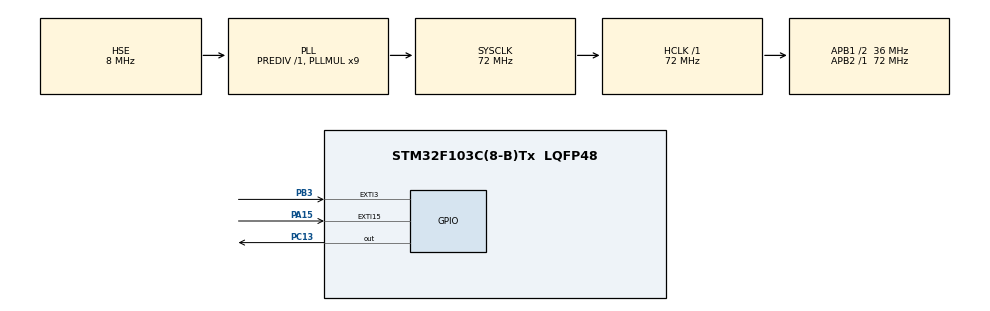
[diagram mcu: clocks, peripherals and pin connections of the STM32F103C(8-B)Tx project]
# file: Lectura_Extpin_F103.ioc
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Mcu.Family=STM32F1
Mcu.Name=STM32F103C(8-B)Tx
Mcu.Package=LQFP48
NVIC.EXTI15_10_IRQn=true\:0\:0\:false\:false\:true\:true\:true\:true
NVIC.EXTI3_IRQn=true\:0\:0\:false\:false\:true\:true\:true\:true
NVIC.PriorityGroup=NVIC_PRIORITYGROUP_4
PA13.Mode=Serial_Wire
PA13.Signal=SYS_JTMS-SWDIO
PA14.Mode=Serial_Wire
PA14.Signal=SYS_JTCK-SWCLK
PA15.Signal=GPXTI15
PB3.GPIO_ModeDefaultEXTI=GPIO_MODE_IT_FALLING
PB3.Signal=GPXTI3
PC13-TAMPER-RTC.Signal=GPIO_Output
PD0-OSC_IN.Mode=HSE-External-Oscillator
PD0-OSC_IN.Signal=RCC_OSC_IN
PD1-OSC_OUT.Mode=HSE-External-Oscillator
PD1-OSC_OUT.Signal=RCC_OSC_OUT
ProjectManager.HeapSize=0x200
ProjectManager.StackSize=0x400
ProjectManager.TargetToolchain=STM32CubeIDE
RCC.AHBFreq_Value=72000000
RCC.APB1CLKDivider=RCC_HCLK_DIV2
RCC.APB1Freq_Value=36000000
RCC.APB1TimFreq_Value=72000000
RCC.APB2Freq_Value=72000000
RCC.APB2TimFreq_Value=72000000
RCC.HCLKFreq_Value=72000000
RCC.PLLMUL=RCC_PLL_MUL9
RCC.PLLSourceVirtual=RCC_PLLSOURCE_HSE
RCC.SYSCLKFreq_VALUE=72000000
RCC.SYSCLKSource=RCC_SYSCLKSOURCE_PLLCLK
RCC.USBFreq_Value=72000000
TIM2.Period=720
TIM2.Prescaler=0
VP_TIM2_VS_ClockSourceINT.Mode=Internal
board=custom

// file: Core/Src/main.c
/* USER CODE BEGIN Header */
/**
  ******************************************************************************
  * @file           : main.c
  * @brief          : Main program body
  ******************************************************************************
  * @attention
  *
  * Copyright (c) 2023 STMicroelectronics.
  * All rights reserved.
  *
  * This software is licensed under terms that can be found in the LICENSE file
  * in the root directory of this software component.
  * If no LICENSE file comes with this software, it is provided AS-IS.
  *
  ******************************************************************************
  */
/* USER CODE END Header */
#include "main.h"

/* USER CODE BEGIN Includes */
#define TIMCLOCK   72000000
#define PRESCALAR  0
#define ARR 0x2D0
#define cant 150
/* USER CODE END Includes */

TIM_HandleTypeDef htim2;

/* USER CODE BEGIN PV */
uint32_t IC_Val1 = 0;
uint32_t IC_Val2 = 0;
uint32_t Difference = 0;
uint32_t usWidth[150];
float refClock=0;
float mFactor=0;
int cont=0;
int flag_pines=0;
int flag_menor=0;
uint32_t min=0;
int cant_min=0;
/* USER CODE END PV */

void SystemClock_Config(void);
static void MX_GPIO_Init(void);
static void MX_TIM2_Init(void);

/* USER CODE BEGIN 0 */
void HAL_GPIO_EXTI_Callback(uint16_t GPIO_Pin) //Interrupcion Externa del pin A1
{
	HAL_GPIO_WritePin(GPIOC, GPIO_PIN_13, GPIO_PIN_RESET);
    if(GPIO_Pin == GPIO_PIN_3) // Chequeo que sea el Pin B3 con bajo
    {
    	HAL_NVIC_DisableIRQ(EXTI3_IRQn); //desactiva las interrupciones externas
    	IC_Val1 =__HAL_TIM_GET_COUNTER(&htim2);

    }
    else if(GPIO_Pin == GPIO_PIN_15 && IC_Val1!=0) // Chequeo que sea el Pin A15 con alto
    {
    	IC_Val2 =__HAL_TIM_GET_COUNTER(&htim2);
    	HAL_NVIC_DisableIRQ(EXTI15_10_IRQn); //desactiva las interrupciones externas
    	flag_pines=1;//Activa la bendera para el calculo
    }
    HAL_GPIO_WritePin(GPIOC, GPIO_PIN_13, GPIO_PIN_SET);

}
/* USER CODE END 0 */

int main(void)
{

  /* MCU Configuration--------------------------------------------------------*/

  /* Reset of all peripherals, Initializes the Flash interface and the Systick. */
  HAL_Init();

  /* Configure the system clock */
  SystemClock_Config();

  /* Initialize all configured peripherals */
  MX_GPIO_Init();
  MX_TIM2_Init();
  /* USER CODE BEGIN 2 */
  HAL_TIM_Base_Start(&htim2);
  /* USER CODE END 2 */

  /* Infinite loop */
  /* USER CODE BEGIN WHILE */
  while (1)
  {
	  if (flag_pines==1)
	  {
		  if (IC_Val2 > IC_Val1)
		  {
			  Difference = IC_Val2-IC_Val1;
		  }
		  else if (IC_Val1 > IC_Val2)
		  {
			  Difference = (ARR - IC_Val1) + IC_Val2;
		  }
		  refClock = TIMCLOCK/(PRESCALAR+1);
		  //mFactor = 1000000/refClock;
		  if (cont<=cant)
		  {
			  usWidth[cont]= Difference;
			  IC_Val1=0;
			  IC_Val2=0;
			  cont++;
			  HAL_NVIC_EnableIRQ(EXTI3_IRQn);
			  HAL_NVIC_EnableIRQ(EXTI15_10_IRQn);
		  }
		  else
		  {
			  flag_menor=1;
		  }
		  flag_pines=0;
	  }
	  if (flag_menor==1)
	  {
		  min=usWidth[0];
		  for (int i=0;i<=149;i++)
		  {
			  if (usWidth[i]< min && usWidth[i]!=0)
			  {
				  min = usWidth[i];
			  }
		  }

		  for (int i=0;i<=149;i++)
		  {
			  if (usWidth[i]==min)
			  {
				  cant_min++;
			  }
		  }
		  flag_menor=0;
	  }
    /* USER CODE END WHILE */

  }
}

void SystemClock_Config(void)
{
  RCC_OscInitTypeDef RCC_OscInitStruct = {0};
  RCC_ClkInitTypeDef RCC_ClkInitStruct = {0};

  /** Initializes the RCC Oscillators according to the specified parameters
  * in the RCC_OscInitTypeDef structure.
  */
  RCC_OscInitStruct.OscillatorType = RCC_OSCILLATORTYPE_HSE;
  RCC_OscInitStruct.HSEState = RCC_HSE_ON;
  RCC_OscInitStruct.HSEPredivValue = RCC_HSE_PREDIV_DIV1;
  RCC_OscInitStruct.HSIState = RCC_HSI_ON;
  RCC_OscInitStruct.PLL.PLLState = RCC_PLL_ON;
  RCC_OscInitStruct.PLL.PLLSource = RCC_PLLSOURCE_HSE;
  RCC_OscInitStruct.PLL.PLLMUL = RCC_PLL_MUL9;
  if (HAL_RCC_OscConfig(&RCC_OscInitStruct) != HAL_OK)
  {
    Error_Handler();
  }

  /** Initializes the CPU, AHB and APB buses clocks
  */
  RCC_ClkInitStruct.ClockType = RCC_CLOCKTYPE_HCLK|RCC_CLOCKTYPE_SYSCLK
                              |RCC_CLOCKTYPE_PCLK1|RCC_CLOCKTYPE_PCLK2;
  RCC_ClkInitStruct.SYSCLKSource = RCC_SYSCLKSOURCE_PLLCLK;
  RCC_ClkInitStruct.AHBCLKDivider = RCC_SYSCLK_DIV1;
  RCC_ClkInitStruct.APB1CLKDivider = RCC_HCLK_DIV2;
  RCC_ClkInitStruct.APB2CLKDivider = RCC_HCLK_DIV1;

  if (HAL_RCC_ClockConfig(&RCC_ClkInitStruct, FLASH_LATENCY_2) != HAL_OK)
  {
    Error_Handler();
  }
}

static void MX_TIM2_Init(void)
{

  TIM_ClockConfigTypeDef sClockSourceConfig = {0};
  TIM_MasterConfigTypeDef sMasterConfig = {0};

  htim2.Instance = TIM2;
  htim2.Init.Prescaler = 0;
  htim2.Init.CounterMode = TIM_COUNTERMODE_UP;
  htim2.Init.Period = 720;
  htim2.Init.ClockDivision = TIM_CLOCKDIVISION_DIV1;
  htim2.Init.AutoReloadPreload = TIM_AUTORELOAD_PRELOAD_DISABLE;
  if (HAL_TIM_Base_Init(&htim2) != HAL_OK)
  {
    Error_Handler();
  }
  sClockSourceConfig.ClockSource = TIM_CLOCKSOURCE_INTERNAL;
  if (HAL_TIM_ConfigClockSource(&htim2, &sClockSourceConfig) != HAL_OK)
  {
    Error_Handler();
  }
  sMasterConfig.MasterOutputTrigger = TIM_TRGO_RESET;
  sMasterConfig.MasterSlaveMode = TIM_MASTERSLAVEMODE_DISABLE;
  if (HAL_TIMEx_MasterConfigSynchronization(&htim2, &sMasterConfig) != HAL_OK)
  {
    Error_Handler();
  }

}

static void MX_GPIO_Init(void)
{
  GPIO_InitTypeDef GPIO_InitStruct = {0};

  /* GPIO Ports Clock Enable */
  __HAL_RCC_GPIOC_CLK_ENABLE();
  __HAL_RCC_GPIOD_CLK_ENABLE();
  __HAL_RCC_GPIOA_CLK_ENABLE();
  __HAL_RCC_GPIOB_CLK_ENABLE();

  /*Configure GPIO pin Output Level */
  HAL_GPIO_WritePin(GPIOC, GPIO_PIN_13, GPIO_PIN_RESET);

  /*Configure GPIO pin : PC13 */
  GPIO_InitStruct.Pin = GPIO_PIN_13;
  GPIO_InitStruct.Mode = GPIO_MODE_OUTPUT_PP;
  GPIO_InitStruct.Pull = GPIO_NOPULL;
  GPIO_InitStruct.Speed = GPIO_SPEED_FREQ_LOW;
  HAL_GPIO_Init(GPIOC, &GPIO_InitStruct);

  /*Configure GPIO pin : PA15 */
  GPIO_InitStruct.Pin = GPIO_PIN_15;
  GPIO_InitStruct.Mode = GPIO_MODE_IT_RISING;
  GPIO_InitStruct.Pull = GPIO_NOPULL;
  HAL_GPIO_Init(GPIOA, &GPIO_InitStruct);

  /*Configure GPIO pin : PB3 */
  GPIO_InitStruct.Pin = GPIO_PIN_3;
  GPIO_InitStruct.Mode = GPIO_MODE_IT_FALLING;
  GPIO_InitStruct.Pull = GPIO_NOPULL;
  HAL_GPIO_Init(GPIOB, &GPIO_InitStruct);

  /* EXTI interrupt init*/
  HAL_NVIC_SetPriority(EXTI3_IRQn, 0, 0);
  HAL_NVIC_EnableIRQ(EXTI3_IRQn);

  HAL_NVIC_SetPriority(EXTI15_10_IRQn, 0, 0);
  HAL_NVIC_EnableIRQ(EXTI15_10_IRQn);

}

void Error_Handler(void)
{
  __disable_irq();
  while (1)
  {
  }
}
